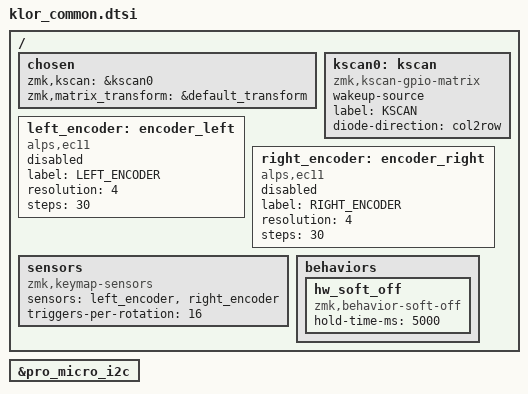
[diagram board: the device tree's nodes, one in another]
/*
 * Copyright (c) 2022 The ZMK Contributors
 *
 * SPDX-License-Identifier: MIT
 */

#include <dt-bindings/zmk/matrix_transform.h>

/ {
	chosen {
		zmk,kscan = &kscan0;
		zmk,matrix_transform = &default_transform;
	};

	kscan0: kscan {
		compatible = "zmk,kscan-gpio-matrix";
		wakeup-source;
		label = "KSCAN";

		diode-direction = "col2row";		
	};

	left_encoder: encoder_left {
		compatible = "alps,ec11";
		label = "LEFT_ENCODER";
		resolution = <4>;
        steps = <30>;
		status = "disabled";
	};

	right_encoder: encoder_right {
		compatible = "alps,ec11";
		label = "RIGHT_ENCODER";
		resolution = <4>;
        steps = <30>;
		status = "disabled";
	};

	sensors {
		compatible = "zmk,keymap-sensors";
		sensors = <&left_encoder &right_encoder>;
        triggers-per-rotation = <16>;
	};

	behaviors {
	        hw_soft_off: hw_soft_off {
	            compatible = "zmk,behavior-soft-off";
	            #binding-cells = <0>;
	            hold-time-ms = <5000>;
	        };
   	};

};

&pro_micro_i2c {
	status = "okay";
};
